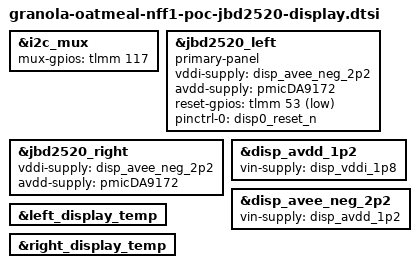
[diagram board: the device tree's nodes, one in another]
// SPDX-License-Identifier: GPL-2.0

#include "granola-jbd2520-display-common.dtsi"
#include "granola-oatmeal-nff1-poc-display-gpios.dtsi"

&i2c_mux {
	mux-gpios = <&tlmm 117 GPIO_ACTIVE_HIGH>;
};

&jbd2520_left {
	primary-panel;
	vddi-supply = <&disp_avee_neg_2p2>;
	avdd-supply = <&pmicDA9172>;

	reset-gpios = <&tlmm 53 GPIO_ACTIVE_LOW>;
	pinctrl-names = "default";
	pinctrl-0 = <&disp0_reset_n>;
};

&jbd2520_right {
	vddi-supply = <&disp_avee_neg_2p2>;
	avdd-supply = <&pmicDA9172>;
};

/* Chain regulators so they can be enabled/disabled together. */
&disp_avdd_1p2 {
	vin-supply = <&disp_vddi_1p8>;
};

&disp_avee_neg_2p2 {
	vin-supply = <&disp_avdd_1p2>;
};

&left_display_temp {
	status = "okay";
};

&right_display_temp {
	status = "okay";
};
